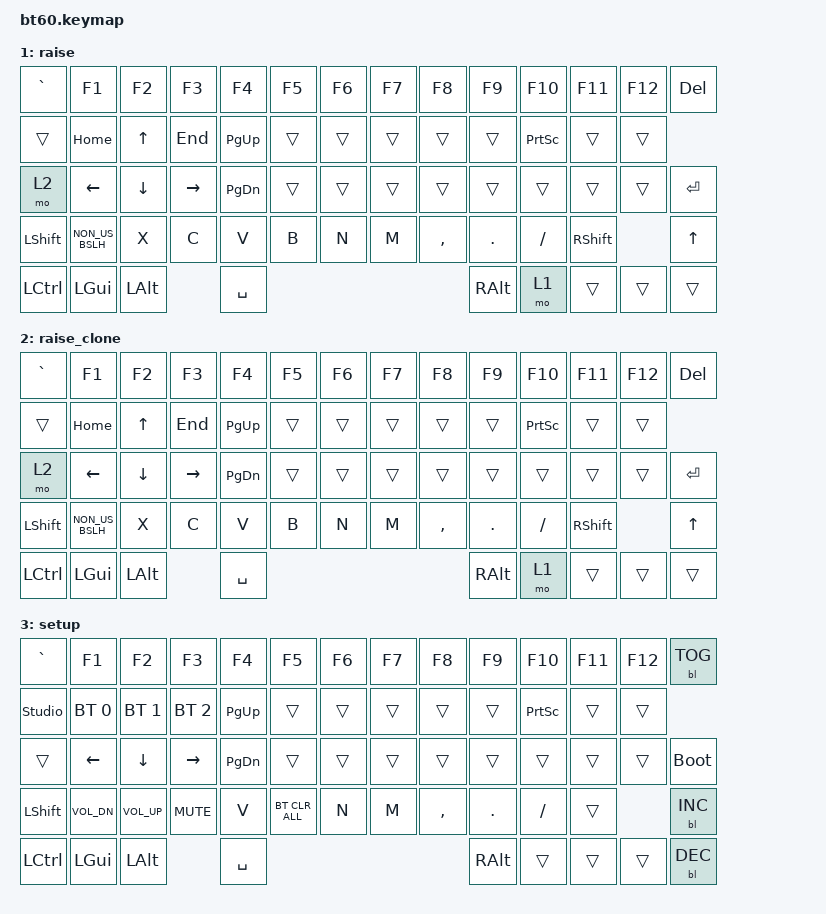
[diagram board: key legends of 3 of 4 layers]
#include <behaviors.dtsi>
#include <dt-bindings/zmk/keys.h>
#include <dt-bindings/zmk/bt.h>
#include <dt-bindings/zmk/rgb.h>
#include <dt-bindings/zmk/backlight.h>

/ {

	  conditional_layers {
            compatible = "zmk,conditional-layers";
            config_from_default {
                if-layers = <1 2>;
                then-layer = <3>;
			};
        };
	keymap {
		compatible = "zmk,keymap";

		default_layer {
				// ------------------------------------------------------------------------------------------
				// | ESC |  1  |  2  |  3  |  4  |  5  |  6  |  7  |  8  |  9  |  0  |  -  |  =  |BKSP | DEL  |
				// | TAB  |  Q  |  W  |  E  |  R  |  T  |  Y  |  U  |  I  |  O  |  P  |  [  |  ]  | ENTER     |
				// | CAPS  |  A  |  S  |  D  |  F  |  G  |  H  |  J  |  K  |  L  |  ñ  |  {  |  {     |	ENTER |
				// |SHIFT|NONE| Z  |  X  |  C  |  V  |  B  |  N  |  M  |  ,  |  .  | _   | SHFT | UP    | 1   |
				// |  CTL  |  WIN  |  ALT  |            SPACE              | ALT | CTRL | LEFT | DOWN | RIGHT |
				// ------------------------------------------------------------------------------------------
			bindings = <

				&kp ESC 	&kp N1 				&kp N2 			&kp N3 			&kp N4 		&kp N5 		&kp N6 		&kp N7 	&kp  N8   	&kp  N9 	&kp  N0  		&kp MINUS 		&kp EQUAL 		&kp BSPC
				&kp TAB  	&kp Q  				&kp W  			&kp E  			&kp R  		&kp T  		&kp Y  		&kp U  	&kp  I    	&kp  O  	&kp  P   		&kp LBKT 		&kp RBKT   		
				&mo 2  		&kp A  				&kp S  			&kp D  			&kp F  		&kp G 		&kp H  		&kp J  	&kp  K    	&kp  L  	&kp SEMI 		&kp SQT   		&kp BSLH  		&kp RET
				&kp LSHFT  	&kp NON_US_BSLH  &kp Z 		&kp X  			&kp C  			&kp V  		&kp B  		&kp N  		&kp M  	&kp COMMA 	&kp DOT 	&kp FSLH		&kp RSHFT  					&kp UP  		
				&kp LCTRL 	&kp LGUI 			&kp LALT            				&kp SPACE             							&kp RALT  	&mo 1 			&kp LEFT  		&kp DOWN		&kp RIGHT 
			>;
			sensor-bindings = <&inc_dec_kp C_VOL_UP C_VOL_DN>;
		};
		raise {
			bindings = <
				&kp GRAVE 	&kp F1 				&kp F2 			&kp F3 			&kp F4 		&kp F5 		&kp F6 		&kp F7 	&kp F8 		&kp F9 		&kp F10 		&kp F11 		&kp F12 		&kp DEL
				&trans 		&kp HOME 			&kp UP 			&kp END 		&kp PG_UP	&trans 		&trans 		&trans 	&trans		&trans 		&kp PSCRN 		&trans	 		&trans		  	
				&mo 2	  	&kp LEFT 			&kp DOWN 		&kp RIGHT 		&kp PG_DN	&trans 		&trans 		&trans 	&trans 		&trans 		&trans			&trans	 		&trans 			&kp RET
				&kp LSHFT  	&kp NON_US_BSLH 		&kp X  			&kp C  			&kp V  		&kp B  		&kp N  		&kp M  	&kp COMMA 	&kp DOT 	&kp FSLH  		&kp RSHFT					&kp UP
				&kp LCTRL 	&kp LGUI  			&kp LALT            				&kp SPACE                 				           	&kp RALT   	&mo 1  			&trans 			&trans  		&trans 
			>;
			sensor-bindings = <&inc_dec_kp C_VOL_UP C_VOL_DN>;
		};
		raise_clone {
			bindings = <
				&kp GRAVE 	&kp F1 				&kp F2 			&kp F3 			&kp F4 		&kp F5 		&kp F6 		&kp F7 	&kp F8 		&kp F9 		&kp F10 		&kp F11 		&kp F12 		&kp DEL
				&trans 		&kp HOME 			&kp UP 			&kp END 		&kp PG_UP	&trans 		&trans 		&trans 	&trans		&trans 		&kp PSCRN 		&trans	 		&trans		  	
				&mo 2   	&kp LEFT 			&kp DOWN 		&kp RIGHT 		&kp PG_DN	&trans 		&trans 		&trans 	&trans 		&trans 		&trans			&trans	 		&trans 			&kp RET
				&kp LSHFT  	&kp NON_US_BSLH 		&kp X  			&kp C  			&kp V  		&kp B  		&kp N  		&kp M  	&kp COMMA 	&kp DOT 	&kp FSLH  		&kp RSHFT					&kp UP
				&kp LCTRL 	&kp LGUI  			&kp LALT            				&kp SPACE                 				           	&kp RALT  	&mo 1  			&trans 			&trans  		&trans 
			>;
			sensor-bindings = <&inc_dec_kp C_VOL_UP C_VOL_DN>;
		};
		setup {
			bindings = <
				&kp GRAVE 	&kp F1 				&kp F2 			&kp F3 			&kp F4 		&kp F5 		&kp F6 		&kp F7 	&kp F8 		&kp F9 		&kp F10 		&kp F11 		&kp F12 		&bl BL_TOG
				&studio_unlock	&bt BT_SEL 0			&bt BT_SEL 1  		&bt BT_SEL 2 		&kp PG_UP	&trans 		&trans 		&trans 	&trans		&trans 		&kp PSCRN 		&trans	 		&trans		  	
				&trans	 	&kp LEFT 			&kp DOWN 		&kp RIGHT 		&kp PG_DN	&trans 		&trans 		&trans 	&trans 		&trans 		&trans			&trans	 		&trans 			&bootloader
				&kp LSHFT  	&kp C_VOL_DN 			&kp C_VOL_UP		&kp C_MUTE   		&kp V  		&bt BT_CLR_ALL  &kp N  		&kp M  	&kp COMMA 	&kp DOT 	&kp FSLH  		&trans						&bl BL_INC
				&kp LCTRL 	&kp LGUI  			&kp LALT            				&kp SPACE                 				           	&kp RALT   	&trans 			&trans 			&trans  		&bl BL_DEC
			>;
			sensor-bindings = <&inc_dec_kp C_VOL_UP C_VOL_DN>;
		};
	};
};
